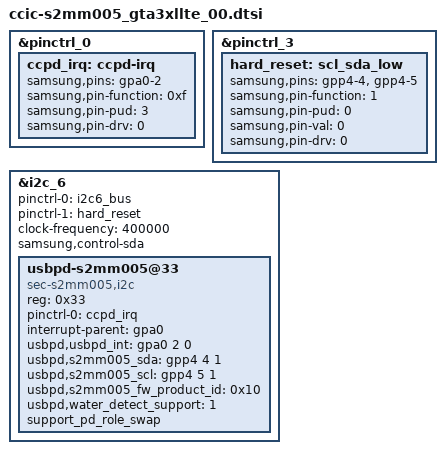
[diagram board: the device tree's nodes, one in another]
/*
 * SAMSUNG Hero Type C S2MM005 CCIC Device Tree Source
 *
 * Copyright (c) 2018 Samsung Electronics Co., Ltd.
 *		http://www.samsung.com
 *
 * This program is free software; you can redistribute it and/or modify
 * it under the terms of the GNU General Public License version 2 as
 * published by the Free Software Foundation.
*/

	&pinctrl_0 {
		ccpd_irq: ccpd-irq {
			samsung,pins = "gpa0-2";
			samsung,pin-function = <0xf>;
			samsung,pin-pud = <3>;
			samsung,pin-drv = <0>;
		};
	};

	&pinctrl_3 {
		hard_reset: scl_sda_low {
			samsung,pins = "gpp4-4", "gpp4-5";
			samsung,pin-function = <1>;
			samsung,pin-pud = <0>;
			samsung,pin-val = <0>;
			samsung,pin-drv = <0>;
		};
	};

	&i2c_6 {
		status = "okay";
		pinctrl-names = "default","hard_reset";
		pinctrl-0 = <&i2c6_bus>;
		pinctrl-1 = <&hard_reset>;
		clock-frequency = <400000>;
		samsung,control-sda;

		usbpd-s2mm005@33 {
			compatible = "sec-s2mm005,i2c";
			reg = <0x33>;
			pinctrl-names = "default";
			pinctrl-0 = <&ccpd_irq>;
			interrupt-parent = <&gpa0>;
			usbpd,usbpd_int = <&gpa0 2 0>;
			usbpd,s2mm005_sda = <&gpp4 4 1>;
			usbpd,s2mm005_scl = <&gpp4 5 1>;
			usbpd,s2mm005_fw_product_id = <0x10>;
			usbpd,water_detect_support = <1>;
			support_pd_role_swap;
		};
	};
